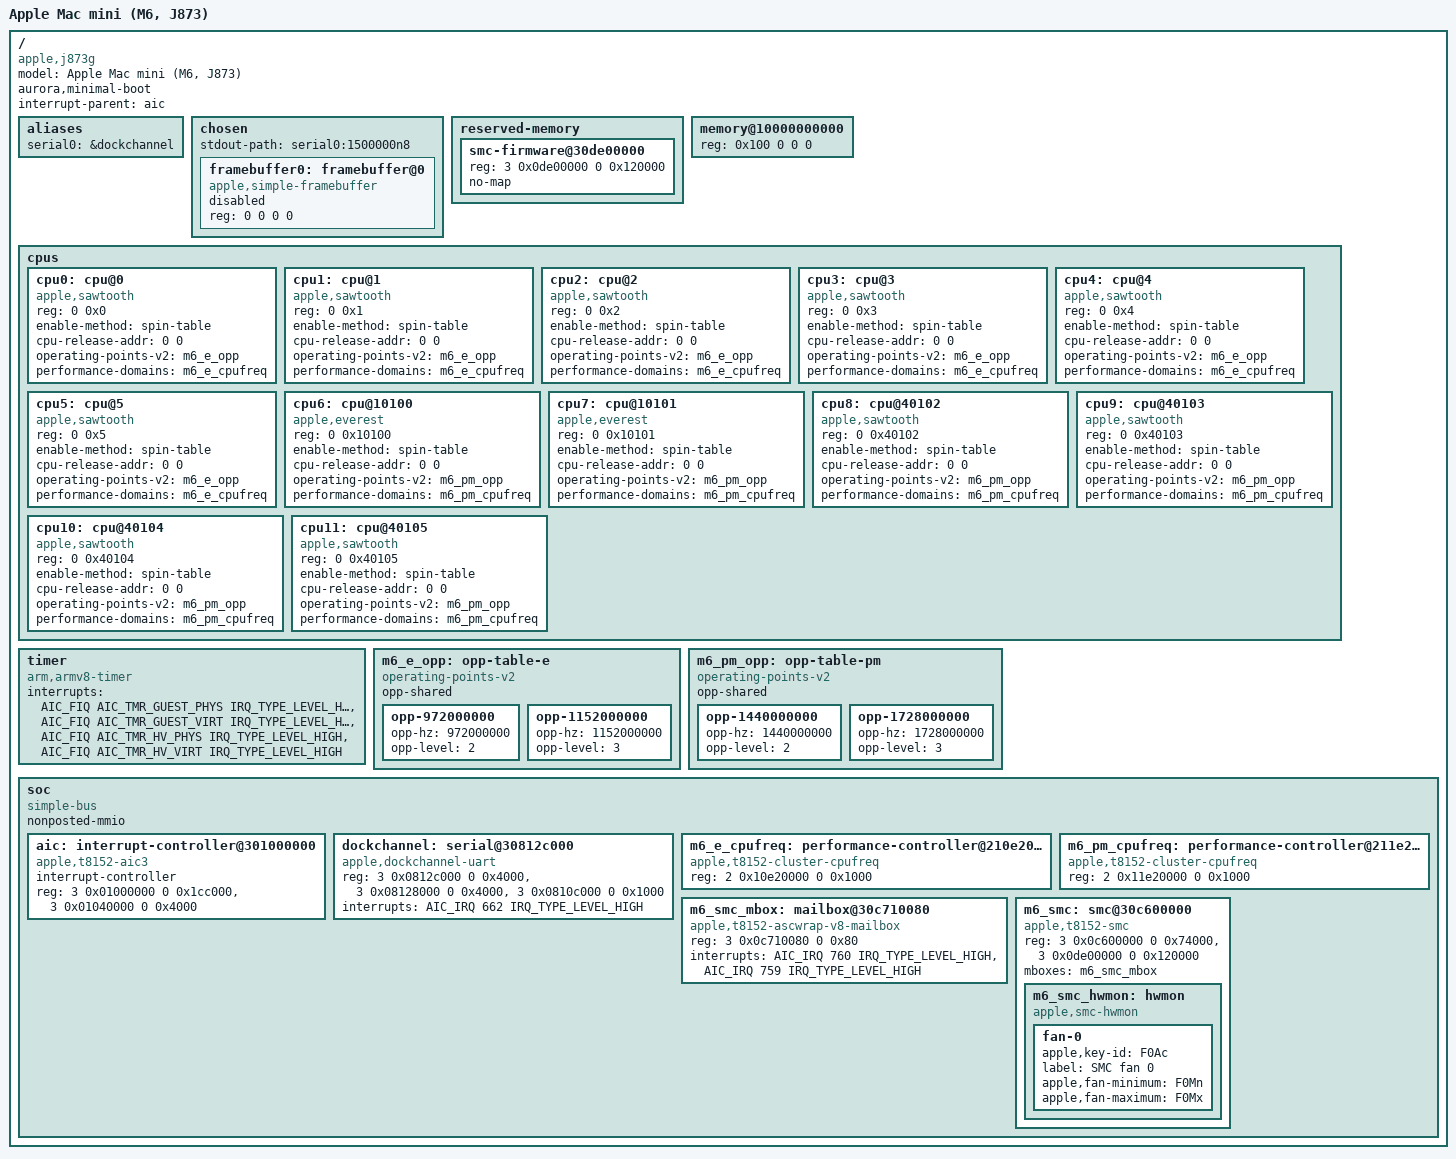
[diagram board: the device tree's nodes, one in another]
// SPDX-License-Identifier: GPL-2.0+ OR MIT
/* J873/T8152 initial Linux thermal bring-up.
 * Addresses, affinities and minimum OPPs are from live J873 evidence.
 * Only the two lowest OPPs are exposed until cooling is qualified.
 * m1n1 supplies usable RAM, the framebuffer and CPU release addresses.
 */
/dts-v1/;
#include <dt-bindings/interrupt-controller/apple-aic.h>
#include <dt-bindings/interrupt-controller/irq.h>
#include <dt-bindings/thermal/thermal.h>
/ {
	compatible = "apple,j873g", "apple,t8152", "apple,arm-platform";
	model = "Apple Mac mini (M6, J873)";
	aurora,minimal-boot;
	#address-cells = <2>;
	#size-cells = <2>;
	interrupt-parent = <&aic>;
	aliases { serial0 = &dockchannel; };
	chosen {
		#address-cells = <2>;
		#size-cells = <2>;
		ranges;
		stdout-path = "serial0:1500000n8";
		framebuffer0: framebuffer@0 {
			compatible = "apple,simple-framebuffer", "simple-framebuffer";
			reg = <0 0 0 0>;
			status = "disabled";
		};
	};
	reserved-memory {
		#address-cells = <2>; #size-cells = <2>; ranges;
		smc-firmware@30de00000 { reg = <3 0x0de00000 0 0x120000>; no-map; };
	};
	memory@10000000000 { device_type = "memory"; reg = <0x100 0 0 0>; };
	cpus {
		#address-cells = <2>;
		#size-cells = <0>;
		cpu0: cpu@0 {
			compatible = "apple,sawtooth";
			device_type = "cpu";
			reg = <0 0x0>;
			enable-method = "spin-table";
			cpu-release-addr = <0 0>;
			operating-points-v2 = <&m6_e_opp>;
			performance-domains = <&m6_e_cpufreq>;
			#cooling-cells = <2>;
		};
		cpu1: cpu@1 {
			compatible = "apple,sawtooth";
			device_type = "cpu";
			reg = <0 0x1>;
			enable-method = "spin-table";
			cpu-release-addr = <0 0>;
			operating-points-v2 = <&m6_e_opp>;
			performance-domains = <&m6_e_cpufreq>;
			#cooling-cells = <2>;
		};
		cpu2: cpu@2 {
			compatible = "apple,sawtooth";
			device_type = "cpu";
			reg = <0 0x2>;
			enable-method = "spin-table";
			cpu-release-addr = <0 0>;
			operating-points-v2 = <&m6_e_opp>;
			performance-domains = <&m6_e_cpufreq>;
			#cooling-cells = <2>;
		};
		cpu3: cpu@3 {
			compatible = "apple,sawtooth";
			device_type = "cpu";
			reg = <0 0x3>;
			enable-method = "spin-table";
			cpu-release-addr = <0 0>;
			operating-points-v2 = <&m6_e_opp>;
			performance-domains = <&m6_e_cpufreq>;
			#cooling-cells = <2>;
		};
		cpu4: cpu@4 {
			compatible = "apple,sawtooth";
			device_type = "cpu";
			reg = <0 0x4>;
			enable-method = "spin-table";
			cpu-release-addr = <0 0>;
			operating-points-v2 = <&m6_e_opp>;
			performance-domains = <&m6_e_cpufreq>;
			#cooling-cells = <2>;
		};
		cpu5: cpu@5 {
			compatible = "apple,sawtooth";
			device_type = "cpu";
			reg = <0 0x5>;
			enable-method = "spin-table";
			cpu-release-addr = <0 0>;
			operating-points-v2 = <&m6_e_opp>;
			performance-domains = <&m6_e_cpufreq>;
			#cooling-cells = <2>;
		};
		cpu6: cpu@10100 {
			compatible = "apple,everest";
			device_type = "cpu";
			reg = <0 0x10100>;
			enable-method = "spin-table";
			cpu-release-addr = <0 0>;
			operating-points-v2 = <&m6_pm_opp>;
			performance-domains = <&m6_pm_cpufreq>;
			#cooling-cells = <2>;
		};
		cpu7: cpu@10101 {
			compatible = "apple,everest";
			device_type = "cpu";
			reg = <0 0x10101>;
			enable-method = "spin-table";
			cpu-release-addr = <0 0>;
			operating-points-v2 = <&m6_pm_opp>;
			performance-domains = <&m6_pm_cpufreq>;
			#cooling-cells = <2>;
		};
		cpu8: cpu@40102 {
			compatible = "apple,sawtooth";
			device_type = "cpu";
			reg = <0 0x40102>;
			enable-method = "spin-table";
			cpu-release-addr = <0 0>;
			operating-points-v2 = <&m6_pm_opp>;
			performance-domains = <&m6_pm_cpufreq>;
			#cooling-cells = <2>;
		};
		cpu9: cpu@40103 {
			compatible = "apple,sawtooth";
			device_type = "cpu";
			reg = <0 0x40103>;
			enable-method = "spin-table";
			cpu-release-addr = <0 0>;
			operating-points-v2 = <&m6_pm_opp>;
			performance-domains = <&m6_pm_cpufreq>;
			#cooling-cells = <2>;
		};
		cpu10: cpu@40104 {
			compatible = "apple,sawtooth";
			device_type = "cpu";
			reg = <0 0x40104>;
			enable-method = "spin-table";
			cpu-release-addr = <0 0>;
			operating-points-v2 = <&m6_pm_opp>;
			performance-domains = <&m6_pm_cpufreq>;
			#cooling-cells = <2>;
		};
		cpu11: cpu@40105 {
			compatible = "apple,sawtooth";
			device_type = "cpu";
			reg = <0 0x40105>;
			enable-method = "spin-table";
			cpu-release-addr = <0 0>;
			operating-points-v2 = <&m6_pm_opp>;
			performance-domains = <&m6_pm_cpufreq>;
			#cooling-cells = <2>;
		};
	};
	timer {
		compatible = "arm,armv8-timer";
		interrupts = <AIC_FIQ AIC_TMR_GUEST_PHYS IRQ_TYPE_LEVEL_HIGH>,
			     <AIC_FIQ AIC_TMR_GUEST_VIRT IRQ_TYPE_LEVEL_HIGH>,
			     <AIC_FIQ AIC_TMR_HV_PHYS IRQ_TYPE_LEVEL_HIGH>,
			     <AIC_FIQ AIC_TMR_HV_VIRT IRQ_TYPE_LEVEL_HIGH>;
		interrupt-names = "phys", "virt", "hyp-phys", "hyp-virt";
	};
	m6_e_opp: opp-table-e {
		compatible = "operating-points-v2"; opp-shared;
		opp-972000000 { opp-hz = /bits/ 64 <972000000>; opp-level = <2>; };
		opp-1152000000 { opp-hz = /bits/ 64 <1152000000>; opp-level = <3>; };
	};
	m6_pm_opp: opp-table-pm {
		compatible = "operating-points-v2"; opp-shared;
		opp-1440000000 { opp-hz = /bits/ 64 <1440000000>; opp-level = <2>; };
		opp-1728000000 { opp-hz = /bits/ 64 <1728000000>; opp-level = <3>; };
	};
	soc {
		compatible = "simple-bus";
		#address-cells = <2>; #size-cells = <2>; ranges; nonposted-mmio;
		aic: interrupt-controller@301000000 {
			compatible = "apple,t8152-aic3";
			interrupt-controller; #interrupt-cells = <3>; #address-cells = <0>;
			reg = <3 0x01000000 0 0x1cc000>, <3 0x01040000 0 0x4000>;
			reg-names = "core", "event";
		};
		dockchannel: serial@30812c000 {
			compatible = "apple,dockchannel-uart";
			reg = <3 0x0812c000 0 0x4000>, <3 0x08128000 0 0x4000>,
			      <3 0x0810c000 0 0x1000>;
			reg-names = "data", "config", "irq";
			interrupts = <AIC_IRQ 662 IRQ_TYPE_LEVEL_HIGH>;
		};
		m6_e_cpufreq: performance-controller@210e20000 {
			compatible = "apple,t8152-cluster-cpufreq";
			reg = <2 0x10e20000 0 0x1000>;
			#performance-domain-cells = <0>;
		};
		m6_pm_cpufreq: performance-controller@211e20000 {
			compatible = "apple,t8152-cluster-cpufreq";
			reg = <2 0x11e20000 0 0x1000>;
			#performance-domain-cells = <0>;
		};
		m6_smc_mbox: mailbox@30c710080 {
			compatible = "apple,t8152-ascwrap-v8-mailbox";
			reg = <3 0x0c710080 0 0x80>;
			/* IRQ 759 follows RX occupancy on physical hardware. */
			interrupts = <AIC_IRQ 760 IRQ_TYPE_LEVEL_HIGH>,
				     <AIC_IRQ 759 IRQ_TYPE_LEVEL_HIGH>;
			interrupt-names = "send-empty", "recv-not-empty";
			#mbox-cells = <0>;
		};
		m6_smc: smc@30c600000 {
			compatible = "apple,t8152-smc";
			reg = <3 0x0c600000 0 0x74000>, <3 0x0de00000 0 0x120000>;
			reg-names = "smc", "sram";
			mboxes = <&m6_smc_mbox>;
			m6_smc_hwmon: hwmon {
				compatible = "apple,smc-hwmon";
				#thermal-sensor-cells = <1>;
				fan-0 {
					apple,key-id = "F0Ac";
					label = "SMC fan 0";
					apple,fan-minimum = "F0Mn";
					apple,fan-maximum = "F0Mx";
				};
			};
		};
	};
};
#include "t8152-j873-thermal-sensors.dtsi"
#include "t8152-j873-gpu.dtsi"
#include "t8152-j873-pmp.dtsi"
#include "t8152-j873-ans.dtsi"
#include "t8152-j873-pmgr.dtsi"
#include "t8152-j873-display.dtsi"
